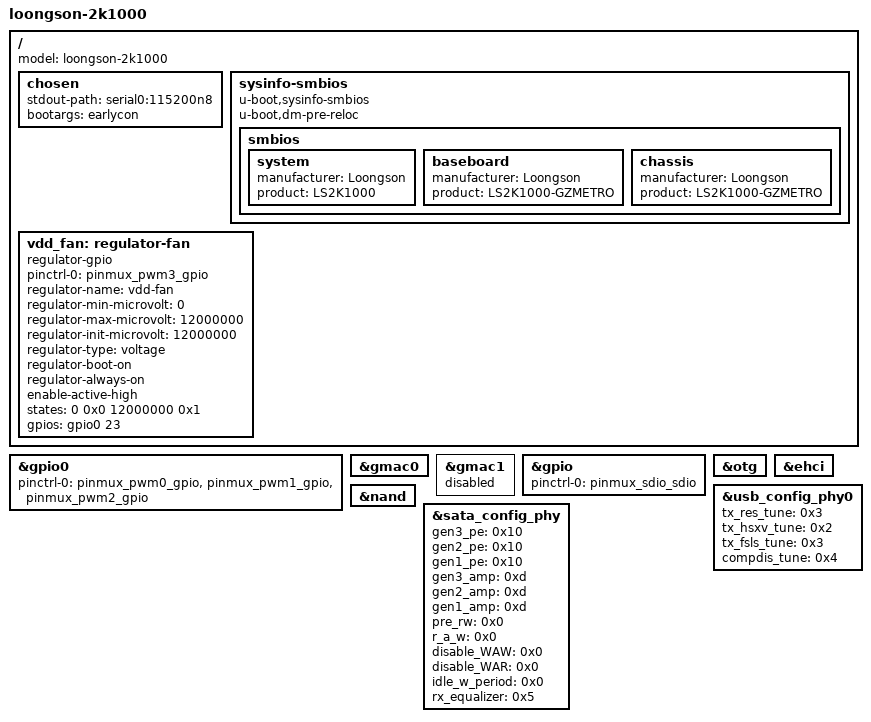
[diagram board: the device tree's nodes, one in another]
#include "ls2k1000_g0_v10.dtsi"
#include <dt-bindings/gpio/gpio.h>

/ {
	model = "loongson-2k1000";

	chosen {
		stdout-path = "serial0:115200n8";
		bootargs = "earlycon";
	};

	sysinfo-smbios {
		compatible = "u-boot,sysinfo-smbios";
		u-boot,dm-pre-reloc;

		smbios {
			system {
				manufacturer = "Loongson";
				product = "LS2K1000";
			};

			baseboard {
				manufacturer = "Loongson";
				product = "LS2K1000-GZMETRO";
			};

			chassis {
				manufacturer = "Loongson";
				product = "LS2K1000-GZMETRO";
			};
		};
	};

	vdd_fan: regulator-fan {
		compatible = "regulator-gpio";
		pinctrl-0 = <&pinmux_pwm3_gpio>;
		pinctrl-names = "default";
		regulator-name = "vdd-fan";
		regulator-min-microvolt = <0>;
		regulator-max-microvolt = <12000000>;
		regulator-init-microvolt = <12000000>;
		regulator-type = "voltage";
		regulator-boot-on;
		regulator-always-on;
		enable-active-high;
		states = <0 0x0 12000000 0x1>;
		gpios = <&gpio0 23 GPIO_ACTIVE_HIGH>;
	};

};

&gpio0 {
	pinctrl-0 = <&pinmux_pwm0_gpio &pinmux_pwm1_gpio &pinmux_pwm2_gpio>;
	pinctrl-names = "default";
};

&gmac0 {
	status = "okay";
};

&gmac1 {
	status = "disable";
};

&gpio {
	pinctrl-0 = <&pinmux_sdio_sdio>;
	pinctrl-names = "default";
};

&otg {
	status = "okay";
};

&ehci {
	status = "okay";
};

&usb_config_phy0 {
	tx_res_tune = <0x3>;
	tx_hsxv_tune = <0x2>;
	tx_fsls_tune = <0x3>;
	compdis_tune = <0x4>;
	status = "okay";
};

&nand {
	status = "okay";
};

&sata_config_phy {
	gen3_pe = <0x10>;
	gen2_pe = <0x10>;
	gen1_pe = <0x10>;
	gen3_amp = <0xd>;
	gen2_amp = <0xd>;
	gen1_amp = <0xd>;
	pre_rw = <0x0>;
	r_a_w = <0x0>;
	disable_WAW = <0x0>;
	disable_WAR = <0x0>;
	idle_w_period = <0x0>;
	rx_equalizer = <0x5>;
	status = "okay";
};

